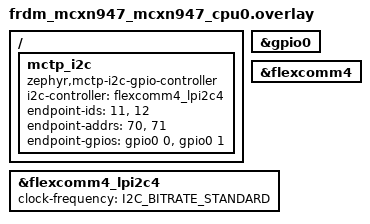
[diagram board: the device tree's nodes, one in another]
/* TODO figure out actually pins/gpios to use for this stuff */

#include <zephyr/dt-bindings/gpio/gpio.h>

&gpio0 {
	status = "okay";
};

&flexcomm4 {
	status = "okay";
};

&flexcomm4_lpi2c4 {
	status = "okay";
	clock-frequency = <I2C_BITRATE_STANDARD>;
};

/ {
	mctp_i2c: mctp_i2c {
		compatible = "zephyr,mctp-i2c-gpio-controller";
		i2c-controller = <&flexcomm4_lpi2c4>;
		endpoint-ids = <11>, <12>;
		endpoint-addrs = <70>, <71>;
		endpoint-gpios = <&gpio0 0 GPIO_ACTIVE_HIGH>, <&gpio0 1 GPIO_ACTIVE_HIGH>;
	};
};
